AUTOSAR XML (schema 4-2-1)
package /ComponentTypes
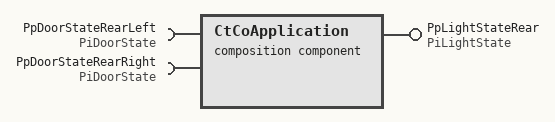
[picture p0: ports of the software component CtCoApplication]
  composition sw component type CtCoApplication
    provide port PpLightStateRear: nonqueued-sender-com-spec{data-element=DeLightState, init-value=constant-reference=CLightOff}, provided-interface=PiLightState
    require port PpDoorStateRearLeft: nonqueued-receiver-com-spec{data-element=DeDoorState, filter=data-filter-type=ALWAYS, init-value=constant-reference=CDoorClosed}, required-interface=PiDoorState
    require port PpDoorStateRearRight: nonqueued-receiver-com-spec{data-element=DeDoorState, filter=data-filter-type=ALWAYS, init-value=constant-reference=CDoorClosed}, required-interface=PiDoorState
    5 x component:
      CpApMySwc: type=CtApMySwc
      CpCddIoHwAb: type=CtCddIoHwAb
      CpSaDoorFrontLeft: type=CtSaDoor
      CpSaDoorFrontRight: type=CtSaDoor
      CpSaInteriorLightFront: type=CtSaInteriorLight
    connect CpApMySwc.PpLightStateFront -> CpSaInteriorLightFront.PpLightState
    connect CpCddIoHwAb.PpDoorFrontLeft -> CpSaDoorFrontLeft.PpDoorIoHwAb
    connect CpCddIoHwAb.PpDoorFrontRight -> CpSaDoorFrontRight.PpDoorIoHwAb
    connect CpCddIoHwAb.PpInteriorLightFrontDEFECT -> CpSaInteriorLightFront.PpInteriorLightDefect
    connect CpCddIoHwAb.PpInteriorLightFront -> CpSaInteriorLightFront.PpInteriorLightIoHwAb
    connect CpSaDoorFrontLeft.PpDoorState -> CpApMySwc.PpDoorStateFrontLeft
    connect CpSaDoorFrontRight.PpDoorState -> CpApMySwc.PpDoorStateFrontRight
    delegate CpApMySwc.PpDoorStateRearLeft <-> outer port PpDoorStateRearLeft
    delegate CpApMySwc.PpDoorStateRearRight <-> outer port PpDoorStateRearRight
    delegate CpApMySwc.PpLightStateRear <-> outer port PpLightStateRear
